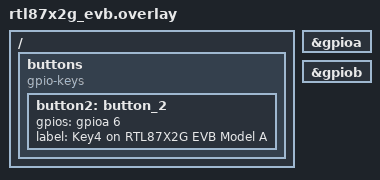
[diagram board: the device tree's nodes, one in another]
/ {
    buttons {
		compatible = "gpio-keys";
		button2: button_2 {
			gpios = <&gpioa 6 GPIO_ACTIVE_HIGH>;
			label = "Key4 on RTL87X2G EVB Model A";
		};
	};
};

&gpioa {
	status = "okay";
};

&gpiob {
	status = "okay";
};
